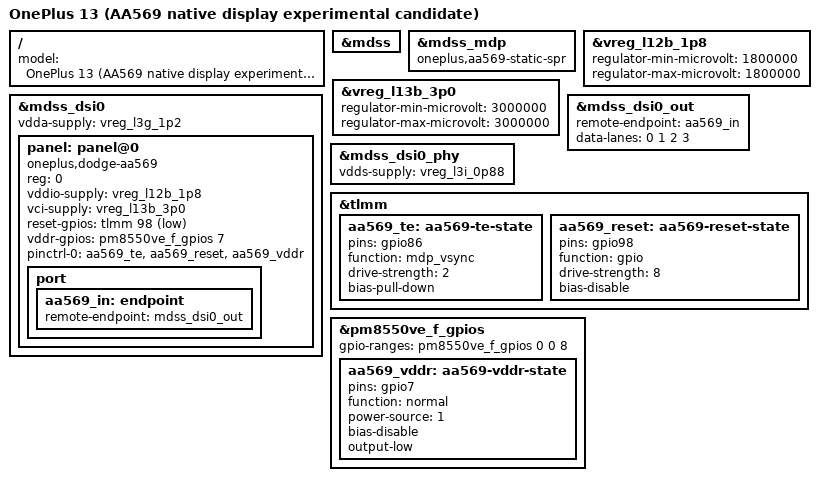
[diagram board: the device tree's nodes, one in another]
// SPDX-License-Identifier: BSD-3-Clause
/* AA569-only experimental display candidate. No touchscreen/radio is enabled.
 * Wiring and supply values match the phone's stock production panel.
 * The required private SPR profile is generated locally, never stored here.
 */
#include "sm8750-oneplus-dodge.dts"

/ { model = "OnePlus 13 (AA569 native display experimental candidate)"; };

&mdss { status = "okay"; };

&mdss_mdp { oneplus,aa569-static-spr; };

&vreg_l12b_1p8 {
	regulator-min-microvolt = <1800000>;
	regulator-max-microvolt = <1800000>;
};

&vreg_l13b_3p0 {
	regulator-min-microvolt = <3000000>;
	regulator-max-microvolt = <3000000>;
};

&mdss_dsi0 {
	vdda-supply = <&vreg_l3g_1p2>;
	status = "okay";

	panel: panel@0 {
		compatible = "oneplus,dodge-aa569";
		reg = <0>;
		vddio-supply = <&vreg_l12b_1p8>;
		vci-supply = <&vreg_l13b_3p0>;
		reset-gpios = <&tlmm 98 GPIO_ACTIVE_LOW>;
		vddr-gpios = <&pm8550ve_f_gpios 7 GPIO_ACTIVE_HIGH>;
		pinctrl-names = "default";
		pinctrl-0 = <&aa569_te>, <&aa569_reset>, <&aa569_vddr>;

		port {
			aa569_in: endpoint {
				remote-endpoint = <&mdss_dsi0_out>;
			};
		};
	};
};

&mdss_dsi0_out {
	remote-endpoint = <&aa569_in>;
	data-lanes = <0 1 2 3>;
};

&mdss_dsi0_phy {
	vdds-supply = <&vreg_l3i_0p88>;
	status = "okay";
};

&tlmm {
	aa569_te: aa569-te-state {
		pins = "gpio86";
		function = "mdp_vsync";
		drive-strength = <2>;
		bias-pull-down;
	};
	aa569_reset: aa569-reset-state {
		pins = "gpio98";
		function = "gpio";
		drive-strength = <8>;
		bias-disable;
	};
};

&pm8550ve_f_gpios {
	/* The actual phone uses pin7; this controller supports eight pins. */
	gpio-ranges = <&pm8550ve_f_gpios 0 0 8>;
	aa569_vddr: aa569-vddr-state {
		pins = "gpio7";
		function = "normal";
		power-source = <1>;
		bias-disable;
		output-low;
	};
};
